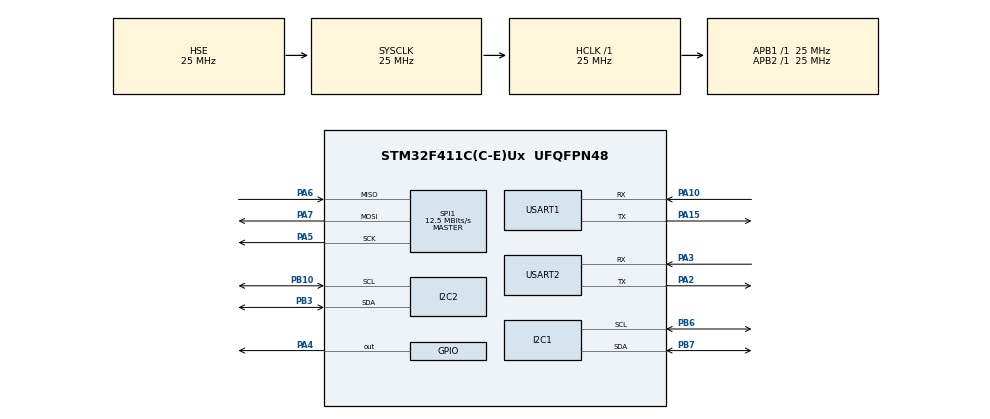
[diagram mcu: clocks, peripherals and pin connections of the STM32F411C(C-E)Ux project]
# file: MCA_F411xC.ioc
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FREERTOS.Tasks01=defaultTask,0,128,StartDefaultTask,Default,NULL,Dynamic,NULL,NULL
Mcu.Family=STM32F4
Mcu.Name=STM32F411C(C-E)Ux
Mcu.Package=UFQFPN48
NVIC.PriorityGroup=NVIC_PRIORITYGROUP_4
NVIC.USART1_IRQn=true\:5\:0\:false\:false\:true\:true\:true\:true
NVIC.USART2_IRQn=true\:5\:0\:false\:false\:true\:true\:true\:true
PA10.Mode=Asynchronous
PA10.Signal=USART1_RX
PA13.Mode=Serial_Wire
PA13.Signal=SYS_JTMS-SWDIO
PA14.Mode=Serial_Wire
PA14.Signal=SYS_JTCK-SWCLK
PA15.Mode=Asynchronous
PA15.Signal=USART1_TX
PA2.Mode=Asynchronous
PA2.Signal=USART2_TX
PA3.Mode=Asynchronous
PA3.Signal=USART2_RX
PA4.Signal=GPIO_Output
PA5.Mode=Full_Duplex_Master
PA5.Signal=SPI1_SCK
PA6.Mode=Full_Duplex_Master
PA6.Signal=SPI1_MISO
PA7.Mode=Full_Duplex_Master
PA7.Signal=SPI1_MOSI
PB10.Mode=I2C
PB10.Signal=I2C2_SCL
PB3.Mode=I2C
PB3.Signal=I2C2_SDA
PB6.Mode=I2C
PB6.Signal=I2C1_SCL
PB7.Mode=I2C
PB7.Signal=I2C1_SDA
PH0\ -\ OSC_IN.Mode=HSE-External-Clock-Source
PH0\ -\ OSC_IN.Signal=RCC_OSC_IN
PH1\ -\ OSC_OUT.Mode=HSE-External-Clock-Source
PH1\ -\ OSC_OUT.Signal=RCC_OSC_OUT
ProjectManager.HeapSize=0x400
ProjectManager.StackSize=0x800
ProjectManager.TargetToolchain=Makefile
RCC.48MHZClocksFreq_Value=26041666.666666664
RCC.AHBFreq_Value=25000000
RCC.APB1Freq_Value=25000000
RCC.APB1TimFreq_Value=25000000
RCC.APB2Freq_Value=25000000
RCC.APB2TimFreq_Value=25000000
RCC.CortexFreq_Value=25000000
RCC.HCLKFreq_Value=25000000
RCC.HSE_VALUE=25000000
RCC.HSI_VALUE=16000000
RCC.LSE_VALUE=32768
RCC.PLLM=12
RCC.PLLN=50
RCC.PLLSourceVirtual=RCC_PLLSOURCE_HSE
RCC.SYSCLKFreq_VALUE=25000000
RCC.SYSCLKSource=RCC_SYSCLKSOURCE_HSE
RCC.VCOOutputFreq_Value=104166666.66666666
SPI1.CalculateBaudRate=12.5 MBits/s
SPI1.Direction=SPI_DIRECTION_2LINES
SPI1.Mode=SPI_MODE_MASTER
SPI1.VirtualType=VM_MASTER
USART1.VirtualMode=VM_ASYNC
USART2.VirtualMode=VM_ASYNC
VP_FATFS_VS_Generic.Mode=User_defined
VP_FREERTOS_VS_CMSIS_V1.Mode=CMSIS_V1
board=custom

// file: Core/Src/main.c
/* USER CODE BEGIN Header */
/**
  ******************************************************************************
  * @file           : main.c
  * @brief          : Main program body
  ******************************************************************************
  * @attention
  *
  * Copyright (c) 2025 STMicroelectronics.
  * All rights reserved.
  *
  * This software is licensed under terms that can be found in the LICENSE file
  * in the root directory of this software component.
  * If no LICENSE file comes with this software, it is provided AS-IS.
  *
  ******************************************************************************
  */
/* USER CODE END Header */
#include "main.h"
#include "cmsis_os.h"
#include "fatfs.h"
#include "MS5611/MS5611.h"
/* USER CODE BEGIN Includes */
#include "common.h"
#include "SDCard/SDCard.h"
#include "MPU/mpu6050.h"
/* USER CODE END Includes */

I2C_HandleTypeDef hi2c1;
I2C_HandleTypeDef hi2c2;

SPI_HandleTypeDef hspi1;

UART_HandleTypeDef huart1;
UART_HandleTypeDef huart2;

osThreadId defaultTaskHandle;
/* USER CODE BEGIN PV */
extern errcode Application_Init(void);
/* USER CODE END PV */

void SystemClock_Config(void);
static void MX_GPIO_Init(void);
static void MX_I2C1_Init(void);
static void MX_I2C2_Init(void);
static void MX_USART1_UART_Init(void);
static void MX_USART2_UART_Init(void);
static void MX_SPI1_Init(void);
void StartDefaultTask(void const * argument);

int main(void)
{

  /* MCU Configuration--------------------------------------------------------*/

  /* Reset of all peripherals, Initializes the Flash interface and the Systick. */
  HAL_Init();

  /* USER CODE BEGIN Init */
  HAL_Delay(1000);
  /* USER CODE END Init */

  /* Configure the system clock */
  SystemClock_Config();

  /* Initialize all configured peripherals */
  MX_GPIO_Init();
  MX_I2C1_Init();
  MX_I2C2_Init();
  MX_USART1_UART_Init();
  MX_USART2_UART_Init();
  MX_SPI1_Init();
  MX_FATFS_Init();
  /* USER CODE BEGIN 2 */
  Application_Init();
  /* USER CODE END 2 */

  /* Create the thread(s) */
  /* definition and creation of defaultTask */
  osThreadDef(defaultTask, StartDefaultTask, osPriorityNormal, 0, 128);
  defaultTaskHandle = osThreadCreate(osThread(defaultTask), NULL);

  /* Start scheduler */
  osKernelStart();

  /* We should never get here as control is now taken by the scheduler */
  /* Infinite loop */
  while (1)
  {

  }
}

void SystemClock_Config(void)
{
  RCC_OscInitTypeDef RCC_OscInitStruct = {0};
  RCC_ClkInitTypeDef RCC_ClkInitStruct = {0};

  /** Configure the main internal regulator output voltage
  */
  __HAL_RCC_PWR_CLK_ENABLE();
  __HAL_PWR_VOLTAGESCALING_CONFIG(PWR_REGULATOR_VOLTAGE_SCALE1);
  /** Initializes the RCC Oscillators according to the specified parameters
  * in the RCC_OscInitTypeDef structure.
  */
  RCC_OscInitStruct.OscillatorType = RCC_OSCILLATORTYPE_HSE;
  RCC_OscInitStruct.HSEState = RCC_HSE_ON;
  RCC_OscInitStruct.PLL.PLLState = RCC_PLL_NONE;
  if (HAL_RCC_OscConfig(&RCC_OscInitStruct) != HAL_OK)
  {
    Error_Handler();
  }
  /** Initializes the CPU, AHB and APB buses clocks
  */
  RCC_ClkInitStruct.ClockType = RCC_CLOCKTYPE_HCLK|RCC_CLOCKTYPE_SYSCLK
                              |RCC_CLOCKTYPE_PCLK1|RCC_CLOCKTYPE_PCLK2;
  RCC_ClkInitStruct.SYSCLKSource = RCC_SYSCLKSOURCE_HSE;
  RCC_ClkInitStruct.AHBCLKDivider = RCC_SYSCLK_DIV1;
  RCC_ClkInitStruct.APB1CLKDivider = RCC_HCLK_DIV1;
  RCC_ClkInitStruct.APB2CLKDivider = RCC_HCLK_DIV1;

  if (HAL_RCC_ClockConfig(&RCC_ClkInitStruct, FLASH_LATENCY_0) != HAL_OK)
  {
    Error_Handler();
  }
}

static void MX_I2C1_Init(void)
{

  hi2c1.Instance = I2C1;
  hi2c1.Init.ClockSpeed = 100000;
  hi2c1.Init.DutyCycle = I2C_DUTYCYCLE_2;
  hi2c1.Init.OwnAddress1 = 0;
  hi2c1.Init.AddressingMode = I2C_ADDRESSINGMODE_7BIT;
  hi2c1.Init.DualAddressMode = I2C_DUALADDRESS_DISABLE;
  hi2c1.Init.OwnAddress2 = 0;
  hi2c1.Init.GeneralCallMode = I2C_GENERALCALL_DISABLE;
  hi2c1.Init.NoStretchMode = I2C_NOSTRETCH_DISABLE;
  if (HAL_I2C_Init(&hi2c1) != HAL_OK)
  {
    Error_Handler();
  }

}

static void MX_I2C2_Init(void)
{

  hi2c2.Instance = I2C2;
  hi2c2.Init.ClockSpeed = 10000;
  hi2c2.Init.DutyCycle = I2C_DUTYCYCLE_2;
  hi2c2.Init.OwnAddress1 = 0;
  hi2c2.Init.AddressingMode = I2C_ADDRESSINGMODE_7BIT;
  hi2c2.Init.DualAddressMode = I2C_DUALADDRESS_DISABLE;
  hi2c2.Init.OwnAddress2 = 0;
  hi2c2.Init.GeneralCallMode = I2C_GENERALCALL_DISABLE;
  hi2c2.Init.NoStretchMode = I2C_NOSTRETCH_DISABLE;
  if (HAL_I2C_Init(&hi2c2) != HAL_OK)
  {
    Error_Handler();
  }

}

static void MX_SPI1_Init(void)
{

  /* SPI1 parameter configuration*/
  hspi1.Instance = SPI1;
  hspi1.Init.Mode = SPI_MODE_MASTER;
  hspi1.Init.Direction = SPI_DIRECTION_2LINES;
  hspi1.Init.DataSize = SPI_DATASIZE_8BIT;
  hspi1.Init.CLKPolarity = SPI_POLARITY_LOW;
  hspi1.Init.CLKPhase = SPI_PHASE_1EDGE;
  hspi1.Init.NSS = SPI_NSS_SOFT;
  hspi1.Init.BaudRatePrescaler = SPI_BAUDRATEPRESCALER_128;
  hspi1.Init.FirstBit = SPI_FIRSTBIT_MSB;
  hspi1.Init.TIMode = SPI_TIMODE_DISABLE;
  hspi1.Init.CRCCalculation = SPI_CRCCALCULATION_DISABLE;
  hspi1.Init.CRCPolynomial = 10;
  if (HAL_SPI_Init(&hspi1) != HAL_OK)
  {
    Error_Handler();
  }

}

static void MX_USART1_UART_Init(void)
{

  huart1.Instance = USART1;
  huart1.Init.BaudRate = 9600;
  huart1.Init.WordLength = UART_WORDLENGTH_8B;
  huart1.Init.StopBits = UART_STOPBITS_1;
  huart1.Init.Parity = UART_PARITY_NONE;
  huart1.Init.Mode = UART_MODE_TX_RX;
  huart1.Init.HwFlowCtl = UART_HWCONTROL_NONE;
  huart1.Init.OverSampling = UART_OVERSAMPLING_16;
  if (HAL_UART_Init(&huart1) != HAL_OK)
  {
    Error_Handler();
  }

}

static void MX_USART2_UART_Init(void)
{

  huart2.Instance = USART2;
  huart2.Init.BaudRate = 115200;
  huart2.Init.WordLength = UART_WORDLENGTH_8B;
  huart2.Init.StopBits = UART_STOPBITS_1;
  huart2.Init.Parity = UART_PARITY_NONE;
  huart2.Init.Mode = UART_MODE_TX_RX;
  huart2.Init.HwFlowCtl = UART_HWCONTROL_NONE;
  huart2.Init.OverSampling = UART_OVERSAMPLING_16;
  if (HAL_UART_Init(&huart2) != HAL_OK)
  {
    Error_Handler();
  }

}

static void MX_GPIO_Init(void)
{
  GPIO_InitTypeDef GPIO_InitStruct = {0};

  /* GPIO Ports Clock Enable */
  __HAL_RCC_GPIOH_CLK_ENABLE();
  __HAL_RCC_GPIOA_CLK_ENABLE();
  __HAL_RCC_GPIOB_CLK_ENABLE();

  /*Configure GPIO pin Output Level */
  HAL_GPIO_WritePin(GPIOA, GPIO_PIN_4, GPIO_PIN_RESET);

  /*Configure GPIO pin : PA4 */
  GPIO_InitStruct.Pin = GPIO_PIN_4;
  GPIO_InitStruct.Mode = GPIO_MODE_OUTPUT_PP;
  GPIO_InitStruct.Pull = GPIO_NOPULL;
  GPIO_InitStruct.Speed = GPIO_SPEED_FREQ_LOW;
  HAL_GPIO_Init(GPIOA, &GPIO_InitStruct);

    /*Configure GPIO pin : PB12 */
  GPIO_InitStruct.Pin = GPIO_PIN_12;
  GPIO_InitStruct.Mode = GPIO_MODE_OUTPUT_PP;
  GPIO_InitStruct.Pull = GPIO_PULLDOWN;
  GPIO_InitStruct.Speed = GPIO_SPEED_FREQ_LOW;
  HAL_GPIO_Init(GPIOB, &GPIO_InitStruct);

}

void StartDefaultTask(void const * argument)
{
  // /* USER CODE BEGIN 5 */
  // mpu_init();
  /* Infinite loop */
  for(;;)
  {
    osDelay(100);
  }
  /* USER CODE END 5 */
}

void Error_Handler(void)
{
  __disable_irq();
  while (1)
  {
  }
}
